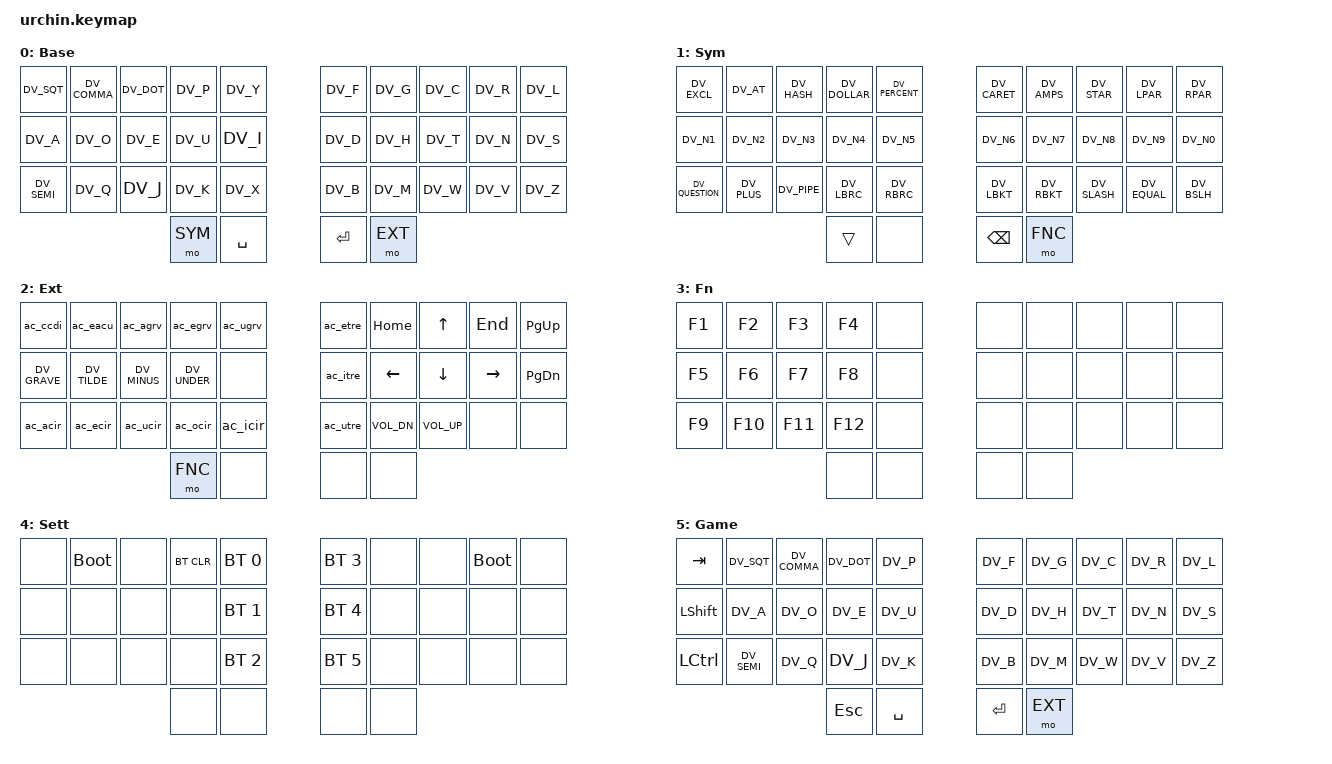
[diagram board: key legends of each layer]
/*
 * Copyright (c) 2020 duckyb
 *
 * SPDX-License-Identifier: MIT
 */

#include <behaviors.dtsi>
#include <dt-bindings/zmk/keys.h>
#include <dt-bindings/zmk/bt.h>
#include <dt-bindings/zmk/outputs.h>
#include <locale/keys_dvorak.h>
#include "accents.dtsi"

// Layer definitions
#define BASE 0
#define SYM 1
#define EXT 2
#define FNC 3
#define SETTINGS 4
#define GAME 5
// -----------------

// Behaviors Constants
#define TAPPING_TERM_MS 280
#define QUICK_TAP_MS 175
#define REQUIRE_PRIOR_IDLE_MS 150

// Combos Constants
#define COMBO_TERM_DEFAULT 30
#define COMBO_QUICK_TAP_MS 100

// Key positions per hand
#define KEYS_L 0 1 2 3 4 10 11 12 13 14 20 21 22 23 24
#define KEYS_R 5 6 7 8 9 15 16 17 18 19 25 26 27 28 29
#define THUMBS 30 31 32 33

#define COMBO(NAME, BINDINGS, KEYPOS, LAYERS) \
  combo_##NAME { \
    timeout-ms = <COMBO_TERM_DEFAULT>; \
    require-prior-idle-ms = <COMBO_QUICK_TAP_MS>; \
    bindings = <BINDINGS>; \
    key-positions = <KEYPOS>; \
    layers = <LAYERS>; \
  };

/ {
	behaviors {
		qt: quick_tap {
			bindings = <&kp>, <&kp>;
			compatible = "zmk,behavior-hold-tap";
			label = "QUICK_TAP";
			flavor = "balanced";
            tapping-term-ms = <TAPPING_TERM_MS>;
            quick-tap-ms = <QUICK_TAP_MS>;
            require-prior-idle-ms = <REQUIRE_PRIOR_IDLE_MS>;
			#binding-cells = <2>;
		};
	};

	macros {};

	combos {
		compatible = "zmk,combos";
	    /*
	      KEY POSITIONS
	      ╭────────────────────╮  ╭────────────────────╮
	      │  0   1   2   3   4 │  │  5   6   7   8   9 │
	      │ 10  11  12  13  14 │  │ 15  16  17  18  19 │
	      │ 20  21  22  23  24 │  │ 25  26  27  28  29 │
	      ╰───────────╮ 30  31 │  │ 32  33 ╭───────────╯
	                  ╰────────╯  ╰────────╯
	    */
		COMBO(settings_l, &sl SETTINGS, 0 20, BASE)
		COMBO(settings_r, &sl SETTINGS, 9 29, BASE)
		COMBO(tab, &kp TAB, 13 14, BASE)
		COMBO(esc, &kp ESC, 15 16, BASE)
		COMBO(capslock, &kp CAPS, 23 24, BASE)
		COMBO(lctrl_l, &kp LCTRL, 2 12, BASE)
		COMBO(lshift_l, &kp LSHIFT, 12 22, BASE)
		COMBO(lgui_l, &kp LGUI, 3 13, BASE)
		COMBO(lalt_l, &kp LALT, 13 23, BASE)
		COMBO(lgui_r, &kp LGUI, 6 16, BASE)
		COMBO(lalt_r, &kp LALT, 16 26, BASE)
		COMBO(lctrl_r, &kp LCTRL, 7 17, BASE)
		COMBO(lshift_r, &kp LSHIFT, 17 27, BASE)
		COMBO(game_l, &to GAME, 4 24, BASE)
		COMBO(base_r, &to BASE, 5 25, GAME)
		COMBO(game_1, &kp 1, 0 10, GAME)
		COMBO(game_2, &kp 2, 1 11, GAME)
		COMBO(game_3, &kp 3, 2 12, GAME)
		COMBO(game_4, &kp 4, 3 13, GAME)
		COMBO(game_5, &kp 5, 4 14, GAME)
	};

	keymap {
		compatible = "zmk,keymap";
		// Base alpha layer
		default_layer {
			label = "Base";
			bindings = <
		// ╭──────────────┬──────────────┬──────────────┬──────────────┬──────────────╮   ╭──────────────┬──────────────┬──────────────┬──────────────┬──────────────╮
		// │0             │1             │2             │3             │4             │   │5             │6             │7             │8             │9             │
		   &kp DV_SQT     &kp DV_COMMA   &kp DV_DOT     &kp DV_P       &kp DV_Y           &kp DV_F       &kp DV_G       &kp DV_C       &kp DV_R       &kp DV_L
		// ├──────────────┼──────────────┼──────────────┼──────────────┼──────────────┤   ├──────────────┼──────────────┼──────────────┼──────────────┼──────────────┤
		// │10            │11            │12            │12            │13            │   │14            │15            │16            │17            │18            │
		   &kp DV_A       &kp DV_O       &kp DV_E       &kp DV_U       &kp DV_I           &kp DV_D       &kp DV_H       &kp DV_T       &kp DV_N       &kp DV_S
		// ├──────────────┼──────────────┼──────────────┼──────────────┼──────────────┤   ├──────────────┼──────────────┼──────────────┼──────────────┼──────────────┤
		// │19            │20            │21            │23            │24            │   │25            │26            │27            │28            │29            │
		   &kp DV_SEMI    &kp DV_Q       &kp DV_J       &kp DV_K       &kp DV_X           &kp DV_B       &kp DV_M       &kp DV_W       &kp DV_V       &kp DV_Z
		// ╰──────────────┴──────────────┴──────────────┼──────────────┼──────────────┤   ├──────────────┼──────────────┼──────────────┴──────────────┴──────────────╯
		//                                              │30            │31            │   │32            │33            │
				                                        &mo SYM        &kp SPACE          &kp ENTER      &mo EXT
		//                                              ╰──────────────┴──────────────╯   ╰──────────────┴──────────────╯
			>;
		};

		// Numbers and high frequency symbols
		sym_layer {
			label = "Sym";
			bindings = <
		// ╭──────────────┬──────────────┬──────────────┬──────────────┬──────────────╮   ╭──────────────┬──────────────┬──────────────┬──────────────┬──────────────╮
		// │0             │1             │2             │3             │4             │   │5             │6             │7             │8             │9             │
		   &kp DV_EXCL    &kp DV_AT      &kp DV_HASH    &kp DV_DOLLAR  &kp DV_PERCENT     &kp DV_CARET   &kp DV_AMPS    &kp DV_STAR    &kp DV_LPAR    &kp DV_RPAR 
		// ├──────────────┼──────────────┼──────────────┼──────────────┼──────────────┤   ├──────────────┼──────────────┼──────────────┼──────────────┼──────────────┤
		// │10            │11            │12            │12            │13            │   │14            │15            │16            │17            │18            │
		   &kp DV_N1      &kp DV_N2      &kp DV_N3      &kp DV_N4      &kp DV_N5          &kp DV_N6      &kp DV_N7      &kp DV_N8      &kp DV_N9      &kp DV_N0
		// ├──────────────┼──────────────┼──────────────┼──────────────┼──────────────┤   ├──────────────┼──────────────┼──────────────┼──────────────┼──────────────┤
		// │19            │20            │21            │23            │24            │   │25            │26            │27            │28            │29            │
		   &kp DV_QUESTION&kp DV_PLUS    &kp DV_PIPE    &kp DV_LBRC    &kp DV_RBRC        &kp DV_LBKT    &kp DV_RBKT     &kp DV_SLASH  &kp DV_EQUAL   &kp DV_BSLH 
		// ╰──────────────┴──────────────┴──────────────┼──────────────┼──────────────┤   ├──────────────┼──────────────┼──────────────┴──────────────┴──────────────╯
		//                                              │30            │31            │   │32            │33            │
												        &trans         &none              &kp BSPC       &mo FNC
		//                                              ╰──────────────┴──────────────╯   ╰──────────────┴──────────────╯
			>;
		};

		// Main modifiers and arrow keys
		// `~-_
		// 
		ext_layer {
			label = "Ext";
			bindings = <
		// ╭──────────────┬──────────────┬──────────────┬──────────────┬──────────────╮   ╭──────────────┬──────────────┬──────────────┬──────────────┬──────────────╮
		// │0             │1             │2             │3             │4             │   │5             │6             │7             │8             │9             │
		   &ac_ccdi       &ac_eacu       &ac_agrv       &ac_egrv       &ac_ugrv           &ac_etre       &kp HOME       &kp UP         &kp END        &kp PG_UP 
		// ├──────────────┼──────────────┼──────────────┼──────────────┼──────────────┤   ├──────────────┼──────────────┼──────────────┼──────────────┼──────────────┤
		// │10            │11            │12            │12            │13            │   │14            │15            │16            │17            │18            │
		   &kp DV_GRAVE   &kp DV_TILDE   &kp DV_MINUS   &kp DV_UNDER   &none              &ac_itre       &kp LEFT       &kp DOWN       &kp RIGHT      &kp PG_DN
		// ├──────────────┼──────────────┼──────────────┼──────────────┼──────────────┤   ├──────────────┼──────────────┼──────────────┼──────────────┼──────────────┤
		// │19            │20            │21            │23            │24            │   │25            │26            │27            │28            │29            │
		   &ac_acir       &ac_ecir       &ac_ucir       &ac_ocir       &ac_icir           &ac_utre       &kp C_VOL_DN   &kp C_VOL_UP   &none          &none
		// ╰──────────────┴──────────────┴──────────────┼──────────────┼──────────────┤   ├──────────────┼──────────────┼──────────────┴──────────────┴──────────────╯
		//                                              │30            │31            │   │32            │33            │
												        &mo FNC        &none              &none          &none
		//                                              ╰──────────────┴──────────────╯   ╰──────────────┴──────────────╯
			>;
		};

		// Function keys with modifiers
		fnc_layer {
			label = "Fn";
			bindings = <
		// ╭──────────────┬──────────────┬──────────────┬──────────────┬──────────────╮   ╭──────────────┬──────────────┬──────────────┬──────────────┬──────────────╮
		// │0             │1             │2             │3             │4             │   │5             │6             │7             │8             │9             │
		   &kp F1         &kp F2         &kp F3         &kp F4         &none              &none          &none          &none          &none          &none
		// ├──────────────┼──────────────┼──────────────┼──────────────┼──────────────┤   ├──────────────┼──────────────┼──────────────┼──────────────┼──────────────┤
		// │10            │11            │12            │12            │13            │   │14            │15            │16            │17            │18            │
		   &kp F5         &kp F6         &kp F7         &kp F8         &none              &none          &none          &none          &none          &none
		// ├──────────────┼──────────────┼──────────────┼──────────────┼──────────────┤   ├──────────────┼──────────────┼──────────────┼──────────────┼──────────────┤
		// │19            │20            │21            │23            │24            │   │25            │26            │27            │28            │29            │
		   &kp F9         &kp F10        &kp F11        &kp F12        &none              &none          &none          &none          &none          &none
		// ╰──────────────┴──────────────┴──────────────┼──────────────┼──────────────┤   ├──────────────┼──────────────┼──────────────┴──────────────┴──────────────╯
		//                                              │30            │31            │   │32            │33            │
						                                &none          &none              &none          &none 
		//                                              ╰──────────────┴──────────────╯   ╰──────────────┴──────────────╯
			>;
		};

		// Used to change the keyboard's settings.
		settings_layer {
				label = "Sett";
				bindings = <
		// ╭──────────────┬──────────────┬──────────────┬──────────────┬──────────────╮   ╭──────────────┬──────────────┬──────────────┬──────────────┬──────────────╮
		// │0             │1             │2             │3             │4             │   │5             │6             │7             │8             │9             │
		   &none          &bootloader    &none          &bt BT_CLR     &bt BT_SEL 0       &bt BT_SEL 3   &none          &none          &bootloader    &none
		// ├──────────────┼──────────────┼──────────────┼──────────────┼──────────────┤   ├──────────────┼──────────────┼──────────────┼──────────────┼──────────────┤
		// │10            │11            │12            │12            │13            │   │14            │15            │16            │17            │18            │
		   &none          &none          &none          &none          &bt BT_SEL 1       &bt BT_SEL 4   &none          &none          &none          &none
		// ├──────────────┼──────────────┼──────────────┼──────────────┼──────────────┤   ├──────────────┼──────────────┼──────────────┼──────────────┼──────────────┤
		// │19            │20            │21            │23            │24            │   │25            │26            │27            │28            │29            │
		   &none          &none          &none          &none          &bt BT_SEL 2       &bt BT_SEL 5   &none          &none          &none          &none
		// ╰──────────────┴──────────────┴──────────────┼──────────────┼──────────────┤   ├──────────────┼──────────────┼──────────────┴──────────────┴──────────────╯
		//                                              │30            │31            │   │32            │33            │
									                    &none          &none              &none          &none
		//                                              ╰──────────────┴──────────────╯   ╰──────────────┴──────────────╯
				>;
		};

		// Game Layer 
		game_layer {
			label = "Game";
			bindings = <
		// ╭──────────────┬──────────────┬──────────────┬──────────────┬──────────────╮   ╭──────────────┬──────────────┬──────────────┬──────────────┬──────────────╮
		// │0             │1             │2             │3             │4             │   │5             │6             │7             │8             │9             │
		   &kp TAB        &kp DV_SQT     &kp DV_COMMA   &kp DV_DOT     &kp DV_P           &kp DV_F       &kp DV_G       &kp DV_C       &kp DV_R       &kp DV_L
		// ├──────────────┼──────────────┼──────────────┼──────────────┼──────────────┤   ├──────────────┼──────────────┼──────────────┼──────────────┼──────────────┤
		// │10            │11            │12            │12            │13            │   │14            │15            │16            │17            │18            │
		   &kp LSHIFT     &kp DV_A       &kp DV_O       &kp DV_E       &kp DV_U           &kp DV_D       &kp DV_H       &kp DV_T       &kp DV_N       &kp DV_S
		// ├──────────────┼──────────────┼──────────────┼──────────────┼──────────────┤   ├──────────────┼──────────────┼──────────────┼──────────────┼──────────────┤
		// │19            │20            │21            │23            │24            │   │25            │26            │27            │28            │29            │
		   &kp LCTRL      &kp DV_SEMI    &kp DV_Q       &kp DV_J       &kp DV_K           &kp DV_B       &kp DV_M       &kp DV_W       &kp DV_V       &kp DV_Z
		// ╰──────────────┴──────────────┴──────────────┼──────────────┼──────────────┤   ├──────────────┼──────────────┼──────────────┴──────────────┴──────────────╯
		//                                              │30            │31            │   │32            │33            │
				                                        &kp ESCAPE     &kp SPACE          &kp ENTER      &mo EXT
		//                                              ╰──────────────┴──────────────╯   ╰──────────────┴──────────────╯
			>;
		};
	};
};
